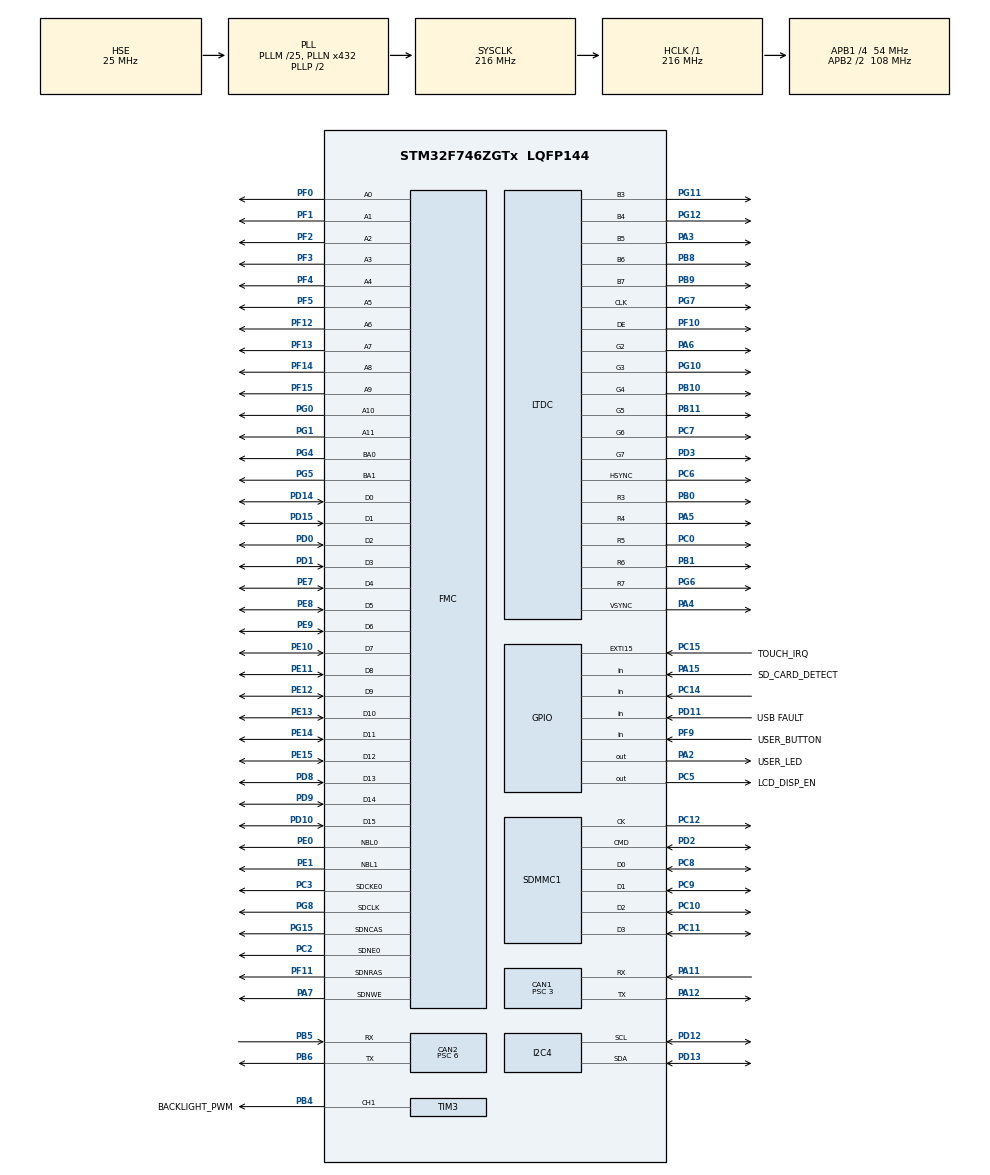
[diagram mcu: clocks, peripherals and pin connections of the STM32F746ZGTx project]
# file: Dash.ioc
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CAN1.BS1=CAN_BS1_14TQ
CAN1.BS2=CAN_BS2_3TQ
CAN1.CalculateBaudRate=1000000
CAN1.CalculateTimeBit=1000
CAN1.CalculateTimeQuantum=55.55555555555556
CAN1.Mode=CAN_MODE_NORMAL
CAN1.NART=ENABLE
CAN1.Prescaler=3
CAN1.SJW=CAN_SJW_4TQ
CAN2.BS1=CAN_BS1_15TQ
CAN2.BS2=CAN_BS2_2TQ
CAN2.CalculateBaudRate=500000
CAN2.CalculateTimeBit=2000
CAN2.CalculateTimeQuantum=111.11111111111111
CAN2.Mode=CAN_MODE_NORMAL
CAN2.NART=ENABLE
CAN2.Prescaler=6
CAN2.SJW=CAN_SJW_2TQ
CORTEX_M7.ART_ACCELERATOR_ENABLE=1
CORTEX_M7.AccessPermission_Spec=MPU_REGION_FULL_ACCESS
CORTEX_M7.BaseAddress_Spec=0xC0000000
CORTEX_M7.CPU_DCache=Enabled
CORTEX_M7.CPU_ICache=Enabled
CORTEX_M7.Enable_Spec=MPU_REGION_ENABLE
CORTEX_M7.IsShareable_Spec=MPU_ACCESS_NOT_SHAREABLE
CORTEX_M7.MPU_Control=MPU_PRIVILEGED_DEFAULT
CORTEX_M7.Size_Spec=MPU_REGION_SIZE_8MB
CORTEX_M7.SubRegionDisable_Spec=0x00
CORTEX_M7.TypeExtField_Spec=MPU_TEX_LEVEL1
CORTEX_M7.default_mode_Activation=1
DMA2D.ColorMode=DMA2D_OUTPUT_RGB565
FATFS.BSP.number=1
FATFS._MAX_SS=4096
FATFS._USE_LFN=2
FATFS0.BSP.STBoard=false
FATFS0.BSP.api=Unknown
FATFS0.BSP.instance=PA15
FATFS0.BSP.ip=GPIO
FATFS0.BSP.mode=Input
FATFS0.BSP.name=Detect_SDIO
FATFS0.BSP.solution=PA15
FMC.CASLatency1=FMC_SDRAM_CAS_LATENCY_3
FMC.ColumnBitsNumber1=FMC_SDRAM_COLUMN_BITS_NUM_9
FMC.ExitSelfRefreshDelay1=8
FMC.LoadToActiveDelay1=2
FMC.RCDDelay1=2
FMC.RPDelay1=2
FMC.RPDelay2=2
FMC.ReadBurst1=FMC_SDRAM_RBURST_ENABLE
FMC.ReadBurst2=FMC_SDRAM_RBURST_ENABLE
FMC.ReadPipeDelay1=FMC_SDRAM_RPIPE_DELAY_2
FMC.ReadPipeDelay2=FMC_SDRAM_RPIPE_DELAY_2
FMC.RowCycleDelay1=7
FMC.RowCycleDelay2=7
FMC.SDClockPeriod1=FMC_SDRAM_CLOCK_PERIOD_2
FMC.SDClockPeriod2=FMC_SDRAM_CLOCK_PERIOD_2
FMC.SelfRefreshTime1=5
FMC.WriteRecoveryTime1=3
FREERTOS.Tasks01=defaultTask,24,2048,StartDefaultTask,Default,NULL,Dynamic,NULL,NULL;canRXTask,24,2048,StartTask02,Default,NULL,Dynamic,NULL,NULL
FREERTOS.configENABLE_FPU=1
FREERTOS.configTOTAL_HEAP_SIZE=32768
I2C4.Timing=0x20404768
LTDC.ActiveW=800
LTDC.Alpha_L0=255
LTDC.BlendingFactor1_L0=LTDC_BLENDING_FACTOR1_PAxCA
LTDC.FBStartAdress_L0=0xC0000000
LTDC.HBP=8
LTDC.HFP=8
LTDC.HSync=4
LTDC.ImageHeight_L0=480
LTDC.ImageWidth_L0=800
LTDC.Layers=0
LTDC.PixelFormat_L0=LTDC_PIXEL_FORMAT_RGB565
LTDC.VBP=8
LTDC.VFP=8
LTDC.WindowX1_L0=800
LTDC.WindowY1_L0=480
Mcu.Family=STM32F7
Mcu.Name=STM32F746ZGTx
Mcu.Package=LQFP144
NVIC.CAN1_RX0_IRQn=true\:5\:0\:false\:false\:true\:true\:true\:true\:true
NVIC.CAN1_RX1_IRQn=true\:5\:0\:false\:false\:true\:true\:true\:true\:true
NVIC.CAN1_SCE_IRQn=true\:5\:0\:false\:false\:true\:true\:true\:true\:true
NVIC.CAN1_TX_IRQn=true\:5\:0\:false\:false\:true\:true\:true\:true\:true
NVIC.CAN2_RX0_IRQn=true\:5\:0\:false\:false\:true\:true\:true\:true\:true
NVIC.CAN2_RX1_IRQn=true\:5\:0\:false\:false\:true\:true\:true\:true\:true
NVIC.CAN2_SCE_IRQn=true\:5\:0\:false\:false\:true\:true\:true\:true\:true
NVIC.CAN2_TX_IRQn=true\:5\:0\:false\:false\:true\:true\:true\:true\:true
NVIC.DMA2D_IRQn=true\:5\:0\:false\:false\:true\:true\:true\:true\:true
NVIC.LTDC_ER_IRQn=true\:5\:0\:false\:false\:true\:true\:true\:true\:true
NVIC.LTDC_IRQn=true\:5\:0\:false\:false\:true\:true\:true\:true\:true
NVIC.PriorityGroup=NVIC_PRIORITYGROUP_4
NVIC.TIM1_UP_TIM10_IRQn=true\:15\:0\:false\:false\:true\:false\:false\:true\:true
NVIC.TimeBase=TIM1_UP_TIM10_IRQn
NVIC.TimeBaseIP=TIM1
PA11.Mode=CAN_Activate
PA11.Signal=CAN1_RX
PA12.Mode=CAN_Activate
PA12.Signal=CAN1_TX
PA13.Mode=Trace_Asynchronous_SW
PA13.Signal=SYS_JTMS-SWDIO
PA14.Mode=Trace_Asynchronous_SW
PA14.Signal=SYS_JTCK-SWCLK
PA15.GPIO_Label=SD_CARD_DETECT
PA15.Signal=GPIO_Input
PA2.GPIO_Label=USER_LED
PA2.Signal=GPIO_Output
PA3.Mode=RGB565
PA3.Signal=LTDC_B5
PA4.Mode=RGB565
PA4.Signal=LTDC_VSYNC
PA5.Mode=RGB565
PA5.Signal=LTDC_R4
PA6.Mode=RGB565
PA6.Signal=LTDC_G2
PA7.Signal=FMC_SDNWE
PB0.Mode=RGB565
PB0.Signal=LTDC_R3
PB1.Mode=RGB565
PB1.Signal=LTDC_R6
PB10.Mode=RGB565
PB10.Signal=LTDC_G4
PB11.Mode=RGB565
PB11.Signal=LTDC_G5
PB3.Mode=Trace_Asynchronous_SW
PB3.Signal=SYS_JTDO-SWO
PB4.GPIO_Label=BACKLIGHT_PWM
PB4.Signal=S_TIM3_CH1
PB5.Mode=CAN_Activate
PB5.Signal=CAN2_RX
PB6.Mode=CAN_Activate
PB6.Signal=CAN2_TX
PB8.Mode=RGB565
PB8.Signal=LTDC_B6
PB9.Mode=RGB565
PB9.Signal=LTDC_B7
PC0.Mode=RGB565
PC0.Signal=LTDC_R5
PC10.GPIO_PuPd=GPIO_NOPULL
PC10.GPIO_Speed_High_Default=GPIO_SPEED_FREQ_LOW
PC10.Mode=SD_4_bits_Wide_bus
PC10.Signal=SDMMC1_D2
PC11.GPIO_PuPd=GPIO_NOPULL
PC11.GPIO_Speed_High_Default=GPIO_SPEED_FREQ_LOW
PC11.Mode=SD_4_bits_Wide_bus
PC11.Signal=SDMMC1_D3
PC12.GPIO_Speed_High_Default=GPIO_SPEED_FREQ_LOW
PC12.Mode=SD_4_bits_Wide_bus
PC12.Signal=SDMMC1_CK
PC14/OSC32_IN.Signal=GPIO_Input
PC15/OSC32_OUT.GPIO_Label=TOUCH_IRQ
PC15/OSC32_OUT.Signal=GPXTI15
PC2.Mode=SdramChipSelect1_1
PC2.Signal=FMC_SDNE0
PC3.Mode=SdramChipSelect1_1
PC3.Signal=FMC_SDCKE0
PC5.GPIO_Label=LCD_DISP_EN
PC5.Signal=GPIO_Output
PC6.Mode=RGB565
PC6.Signal=LTDC_HSYNC
PC7.Mode=RGB565
PC7.Signal=LTDC_G6
PC8.GPIO_PuPd=GPIO_NOPULL
PC8.GPIO_Speed_High_Default=GPIO_SPEED_FREQ_LOW
PC8.Mode=SD_4_bits_Wide_bus
PC8.Signal=SDMMC1_D0
PC9.GPIO_PuPd=GPIO_NOPULL
PC9.GPIO_Speed_High_Default=GPIO_SPEED_FREQ_LOW
PC9.Mode=SD_4_bits_Wide_bus
PC9.Signal=SDMMC1_D1
PD0.Signal=FMC_D2_DA2
PD1.Signal=FMC_D3_DA3
PD10.Signal=FMC_D15_DA15
PD11.GPIO_Label=USB FAULT
PD11.Signal=GPIO_Input
PD12.Mode=I2C
PD12.Signal=I2C4_SCL
PD13.Mode=I2C
PD13.Signal=I2C4_SDA
PD14.Signal=FMC_D0_DA0
PD15.Signal=FMC_D1_DA1
PD2.GPIO_PuPd=GPIO_NOPULL
PD2.GPIO_Speed_High_Default=GPIO_SPEED_FREQ_LOW
PD2.Mode=SD_4_bits_Wide_bus
PD2.Signal=SDMMC1_CMD
PD3.Mode=RGB565
PD3.Signal=LTDC_G7
PD8.Signal=FMC_D13_DA13
PD9.Signal=FMC_D14_DA14
PE0.Signal=FMC_NBL0
PE1.Signal=FMC_NBL1
PE10.Signal=FMC_D7_DA7
PE11.Signal=FMC_D8_DA8
PE12.Signal=FMC_D9_DA9
PE13.Signal=FMC_D10_DA10
PE14.Signal=FMC_D11_DA11
PE15.Signal=FMC_D12_DA12
PE2.Signal=SPI4_SCK
PE4.Signal=SPI4_NSS
PE5.Signal=SPI4_MISO
PE6.Signal=SPI4_MOSI
PE7.Signal=FMC_D4_DA4
PE8.Signal=FMC_D5_DA5
PE9.Signal=FMC_D6_DA6
PF0.Signal=FMC_A0
PF1.Signal=FMC_A1
PF10.Mode=RGB565
PF10.Signal=LTDC_DE
PF11.Signal=FMC_SDNRAS
PF12.Signal=FMC_A6
PF13.Signal=FMC_A7
PF14.Signal=FMC_A8
PF15.Signal=FMC_A9
PF2.Signal=FMC_A2
PF3.Signal=FMC_A3
PF4.Signal=FMC_A4
PF5.Signal=FMC_A5
PF9.GPIO_Label=USER_BUTTON
PF9.Signal=GPIO_Input
PG0.Signal=FMC_A10
PG1.Signal=FMC_A11
PG10.Mode=RGB565
PG10.Signal=LTDC_G3
PG11.Mode=RGB565
PG11.Signal=LTDC_B3
PG12.Mode=RGB565
PG12.Signal=LTDC_B4
PG15.Signal=FMC_SDNCAS
PG4.Signal=FMC_A14_BA0
PG5.Signal=FMC_A15_BA1
PG6.Mode=RGB565
PG6.Signal=LTDC_R7
PG7.Mode=RGB565
PG7.Signal=LTDC_CLK
PG8.Signal=FMC_SDCLK
PH0/OSC_IN.Mode=HSE-External-Oscillator
PH0/OSC_IN.Signal=RCC_OSC_IN
PH1/OSC_OUT.Mode=HSE-External-Oscillator
PH1/OSC_OUT.Signal=RCC_OSC_OUT
ProjectManager.HeapSize=0x400
ProjectManager.StackSize=0x1000
ProjectManager.TargetToolchain=CMake
RCC.AHBFreq_Value=216000000
RCC.APB1CLKDivider=RCC_HCLK_DIV4
RCC.APB1Freq_Value=54000000
RCC.APB1TimFreq_Value=108000000
RCC.APB2CLKDivider=RCC_HCLK_DIV2
RCC.APB2Freq_Value=108000000
RCC.APB2TimFreq_Value=216000000
RCC.CortexFreq_Value=216000000
RCC.HCLKFreq_Value=216000000
RCC.HSE_VALUE=25000000
RCC.HSI_VALUE=16000000
RCC.LSE_VALUE=32768
RCC.PLLM=25
RCC.PLLN=432
RCC.PLLQ=9
RCC.PLLSAIN=100
RCC.PLLSourceVirtual=RCC_PLLSOURCE_HSE
RCC.SDMMCClockSelection=RCC_SDMMC1CLKSOURCE_CLK48
RCC.SYSCLKFreq_VALUE=216000000
RCC.SYSCLKSource=RCC_SYSCLKSOURCE_PLLCLK
RCC.USBFreq_Value=48000000
RCC.VCOOutputFreq_Value=432000000
SDMMC1.ClockDiv=8
SH.FMC_A0.0=FMC_A0,12b-sda1
SH.FMC_A1.0=FMC_A1,12b-sda1
SH.FMC_A10.0=FMC_A10,12b-sda1
SH.FMC_A11.0=FMC_A11,12b-sda1
SH.FMC_A14_BA0.0=FMC_BA0,FourSdramBanks1
SH.FMC_A15_BA1.0=FMC_BA1,FourSdramBanks1
SH.FMC_A2.0=FMC_A2,12b-sda1
SH.FMC_A3.0=FMC_A3,12b-sda1
SH.FMC_A4.0=FMC_A4,12b-sda1
SH.FMC_A5.0=FMC_A5,12b-sda1
SH.FMC_A6.0=FMC_A6,12b-sda1
SH.FMC_A7.0=FMC_A7,12b-sda1
SH.FMC_A8.0=FMC_A8,12b-sda1
SH.FMC_A9.0=FMC_A9,12b-sda1
SH.FMC_D0_DA0.0=FMC_D0,sd-16b-d1
SH.FMC_D10_DA10.0=FMC_D10,sd-16b-d1
SH.FMC_D11_DA11.0=FMC_D11,sd-16b-d1
SH.FMC_D12_DA12.0=FMC_D12,sd-16b-d1
SH.FMC_D13_DA13.0=FMC_D13,sd-16b-d1
SH.FMC_D14_DA14.0=FMC_D14,sd-16b-d1
SH.FMC_D15_DA15.0=FMC_D15,sd-16b-d1
SH.FMC_D1_DA1.0=FMC_D1,sd-16b-d1
SH.FMC_D2_DA2.0=FMC_D2,sd-16b-d1
SH.FMC_D3_DA3.0=FMC_D3,sd-16b-d1
SH.FMC_D4_DA4.0=FMC_D4,sd-16b-d1
SH.FMC_D5_DA5.0=FMC_D5,sd-16b-d1
SH.FMC_D6_DA6.0=FMC_D6,sd-16b-d1
SH.FMC_D7_DA7.0=FMC_D7,sd-16b-d1
SH.FMC_D8_DA8.0=FMC_D8,sd-16b-d1
SH.FMC_D9_DA9.0=FMC_D9,sd-16b-d1
SH.FMC_NBL0.0=FMC_NBL0,Sd2ByteEnable1
SH.FMC_NBL1.0=FMC_NBL1,Sd2ByteEnable1
SH.FMC_SDCLK.0=FMC_SDCLK,12b-sda1
SH.FMC_SDNCAS.0=FMC_SDNCAS,12b-sda1
SH.FMC_SDNRAS.0=FMC_SDNRAS,12b-sda1
SH.FMC_SDNWE.0=FMC_SDNWE,12b-sda1
SH.S_TIM3_CH1.0=TIM3_CH1,PWM Generation1 CH1
TIM3.Channel-PWM\ Generation1\ CH1=TIM_CHANNEL_1
TIM3.Period=10799
VP_CRC_VS_CRC.Mode=CRC_Activate
VP_DMA2D_VS_DMA2D.Mode=DMA2D_Activate
VP_FATFS_VS_SDIO.Mode=SDIO
VP_FREERTOS_VS_CMSIS_V2.Mode=CMSIS_V2
VP_SYS_VS_tim1.Mode=TIM1
board=custom

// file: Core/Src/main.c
/* USER CODE BEGIN Header */
/**
  ******************************************************************************
  * @file           : main.c
  * @brief          : Main program body
  ******************************************************************************
  * @attention
  *
  * Copyright (c) 2026 STMicroelectronics.
  * All rights reserved.
  *
  * This software is licensed under terms that can be found in the LICENSE file
  * in the root directory of this software component.
  * If no LICENSE file comes with this software, it is provided AS-IS.
  *
  ******************************************************************************
  */
/* USER CODE END Header */
#include "main.h"
#include "cmsis_os.h"
#include "can.h"
#include "crc.h"
#include "dma2d.h"
#include "fatfs.h"
#include "i2c.h"
#include "ltdc.h"
#include "sdmmc.h"
#include "tim.h"
#include "gpio.h"
#include "fmc.h"

/* USER CODE BEGIN Includes */
#include "usbd.h"
#include "usb_mode.h"
/* USER CODE END Includes */

/* USER CODE BEGIN PD */
#define SDRAM_ADDRESS_START 0xC0000000	// STM32 Memory Map
#define SDRAM_SIZE 0x1000000			// Total SDRAM # of bytes
/* USER CODE END PD */

/* USER CODE BEGIN PM */
#define TUSB_DEBUG_PRINTF(...)  my_uart_printf(__VA_ARGS__)
/* USER CODE END PM */

/* USER CODE BEGIN PV */
bool msc_mode = false;

/* USER CODE END PV */

void SystemClock_Config(void);
static void MPU_Config(void);
void MX_FREERTOS_Init(void);

int main(void)
{

  /* MPU Configuration--------------------------------------------------------*/
  MPU_Config();

  /* Enable the CPU Cache */

  /* Enable I-Cache---------------------------------------------------------*/
  SCB_EnableICache();

  /* Enable D-Cache---------------------------------------------------------*/
  SCB_EnableDCache();

  /* MCU Configuration--------------------------------------------------------*/

  /* Reset of all peripherals, Initializes the Flash interface and the Systick. */
  HAL_Init();

  /* Configure the system clock */
  SystemClock_Config();

  /* USER CODE BEGIN SysInit */

  __HAL_RCC_GPIOB_CLK_ENABLE();
  HAL_GPIO_WritePin(BACKLIGHT_PWM_GPIO_Port, BACKLIGHT_PWM_Pin, GPIO_PIN_RESET);
  GPIO_InitTypeDef backlight_early_init = {0};
  backlight_early_init.Pin = BACKLIGHT_PWM_Pin;
  backlight_early_init.Mode = GPIO_MODE_OUTPUT_PP;
  backlight_early_init.Pull = GPIO_NOPULL;
  backlight_early_init.Speed = GPIO_SPEED_FREQ_LOW;
  HAL_GPIO_Init(BACKLIGHT_PWM_GPIO_Port, &backlight_early_init);

  /* USER CODE END SysInit */

  /* Initialize all configured peripherals */
  MX_GPIO_Init();
  MX_CAN1_Init();
  MX_CAN2_Init();
  MX_FMC_Init();
  MX_LTDC_Init();
  MX_TIM3_Init();
  MX_SDMMC1_SD_Init();
  MX_FATFS_Init();
  MX_DMA2D_Init();
  MX_CRC_Init();
  MX_I2C4_Init();
  /* USER CODE BEGIN 2 */

  // Read the button state at boot to determine whether to enter MSC mode or normal mode
  msc_mode = (HAL_GPIO_ReadPin(USER_BUTTON_GPIO_Port, USER_BUTTON_Pin) == GPIO_PIN_RESET);

  // Display inits
  HAL_GPIO_WritePin(LCD_DISP_EN_GPIO_Port, LCD_DISP_EN_Pin, GPIO_PIN_SET);
  GPIO_InitTypeDef GPIO_InitStruct = {0};
  GPIO_InitStruct.Pin = BACKLIGHT_PWM_Pin;
  GPIO_InitStruct.Pull = GPIO_NOPULL;
  GPIO_InitStruct.Speed = GPIO_SPEED_FREQ_LOW;
  HAL_GPIO_WritePin(BACKLIGHT_PWM_GPIO_Port, BACKLIGHT_PWM_Pin, GPIO_PIN_SET);
  HAL_Delay(5);
  // Start the Timer in the background to configure brightness
  // (Assuming your Period is set to 10799 in tim.c, 5% is ~540)
  __HAL_TIM_SET_COMPARE(&htim3, TIM_CHANNEL_1, 1800);
  HAL_TIM_PWM_Start(&htim3, TIM_CHANNEL_1);
  // Hand the pin over to the running Timer (Alternate Function 2)
  GPIO_InitStruct.Mode = GPIO_MODE_AF_PP;
  GPIO_InitStruct.Alternate = GPIO_AF2_TIM3;
  HAL_GPIO_Init(BACKLIGHT_PWM_GPIO_Port, &GPIO_InitStruct);

  uint16_t blink_time = 500;

  /* USER CODE END 2 */

  /* Init scheduler */
  osKernelInitialize();  /* Call init function for freertos objects (in cmsis_os2.c) */
  MX_FREERTOS_Init();

  /* Start scheduler */
  osKernelStart();

  /* We should never get here as control is now taken by the scheduler */

  /* Infinite loop */
  while (1)
  {

    /* USER CODE BEGIN 3 */
    tud_task();

    // Non-blocking LED toggle every 500ms
    if (HAL_GetTick() - blink_time >= 500)
    {
        blink_time = HAL_GetTick();
        HAL_GPIO_TogglePin(USER_LED_GPIO_Port, USER_LED_Pin);
    }
  }
  /* USER CODE END 3 */
}

void SystemClock_Config(void)
{
  RCC_OscInitTypeDef RCC_OscInitStruct = {0};
  RCC_ClkInitTypeDef RCC_ClkInitStruct = {0};

  /** Configure the main internal regulator output voltage
  */
  __HAL_RCC_PWR_CLK_ENABLE();
  __HAL_PWR_VOLTAGESCALING_CONFIG(PWR_REGULATOR_VOLTAGE_SCALE1);

  /** Initializes the RCC Oscillators according to the specified parameters
  * in the RCC_OscInitTypeDef structure.
  */
  RCC_OscInitStruct.OscillatorType = RCC_OSCILLATORTYPE_HSE;
  RCC_OscInitStruct.HSEState = RCC_HSE_ON;
  RCC_OscInitStruct.PLL.PLLState = RCC_PLL_ON;
  RCC_OscInitStruct.PLL.PLLSource = RCC_PLLSOURCE_HSE;
  RCC_OscInitStruct.PLL.PLLM = 25;
  RCC_OscInitStruct.PLL.PLLN = 432;
  RCC_OscInitStruct.PLL.PLLP = RCC_PLLP_DIV2;
  RCC_OscInitStruct.PLL.PLLQ = 9;
  if (HAL_RCC_OscConfig(&RCC_OscInitStruct) != HAL_OK)
  {
    Error_Handler();
  }

  /** Activate the Over-Drive mode
  */
  if (HAL_PWREx_EnableOverDrive() != HAL_OK)
  {
    Error_Handler();
  }

  /** Initializes the CPU, AHB and APB buses clocks
  */
  RCC_ClkInitStruct.ClockType = RCC_CLOCKTYPE_HCLK|RCC_CLOCKTYPE_SYSCLK
                              |RCC_CLOCKTYPE_PCLK1|RCC_CLOCKTYPE_PCLK2;
  RCC_ClkInitStruct.SYSCLKSource = RCC_SYSCLKSOURCE_PLLCLK;
  RCC_ClkInitStruct.AHBCLKDivider = RCC_SYSCLK_DIV1;
  RCC_ClkInitStruct.APB1CLKDivider = RCC_HCLK_DIV4;
  RCC_ClkInitStruct.APB2CLKDivider = RCC_HCLK_DIV2;

  if (HAL_RCC_ClockConfig(&RCC_ClkInitStruct, FLASH_LATENCY_7) != HAL_OK)
  {
    Error_Handler();
  }
}

 /* MPU Configuration */

void MPU_Config(void)
{
  MPU_Region_InitTypeDef MPU_InitStruct = {0};

  /* Disables the MPU */
  HAL_MPU_Disable();

  /** Initializes and configures the Region and the memory to be protected
  */
  MPU_InitStruct.Enable = MPU_REGION_ENABLE;
  MPU_InitStruct.Number = MPU_REGION_NUMBER0;
  MPU_InitStruct.BaseAddress = 0xC0000000;
  MPU_InitStruct.Size = MPU_REGION_SIZE_8MB;
  MPU_InitStruct.SubRegionDisable = 0x00;
  MPU_InitStruct.TypeExtField = MPU_TEX_LEVEL1;
  MPU_InitStruct.AccessPermission = MPU_REGION_FULL_ACCESS;
  MPU_InitStruct.DisableExec = MPU_INSTRUCTION_ACCESS_DISABLE;
  MPU_InitStruct.IsShareable = MPU_ACCESS_NOT_SHAREABLE;
  MPU_InitStruct.IsCacheable = MPU_ACCESS_NOT_CACHEABLE;
  MPU_InitStruct.IsBufferable = MPU_ACCESS_NOT_BUFFERABLE;

  HAL_MPU_ConfigRegion(&MPU_InitStruct);
  /* Enables the MPU */
  HAL_MPU_Enable(MPU_PRIVILEGED_DEFAULT);

}

void HAL_TIM_PeriodElapsedCallback(TIM_HandleTypeDef *htim)
{
  if (htim->Instance == TIM1)
  {
    HAL_IncTick();
  }
}

void Error_Handler(void)
{
  __disable_irq();
  while (1)
  {
  }
}

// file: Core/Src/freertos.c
/* USER CODE BEGIN Header */
/**
  ******************************************************************************
  * File Name          : freertos.c
  * Description        : Code for freertos applications
  ******************************************************************************
  * @attention
  *
  * Copyright (c) 2026 STMicroelectronics.
  * All rights reserved.
  *
  * This software is licensed under terms that can be found in the LICENSE file
  * in the root directory of this software component.
  * If no LICENSE file comes with this software, it is provided AS-IS.
  *
  ******************************************************************************
  */
/* USER CODE END Header */

#include "FreeRTOS.h"
#include "task.h"
#include "main.h"
#include "cmsis_os.h"

/* USER CODE BEGIN Includes */
#include <stdbool.h>

#include "can.h"
#include "ltdc.h"
#include "ui.h"
#include "screen_select.h"
/* USER CODE END Includes */

/* USER CODE BEGIN PD */
#ifdef __GNUC__
#define USED __attribute__((used))
#else
#define USED
#endif

volatile const int USED uxTopUsedPriority = configMAX_PRIORITIES - 1;
/* USER CODE END PD */

/* Definitions for defaultTask */
osThreadId_t defaultTaskHandle;
const osThreadAttr_t defaultTask_attributes = {
  .name = "defaultTask",
  .stack_size = 2048 * 4,
  .priority = (osPriority_t) osPriorityNormal,
};
/* Definitions for canRXTask */
osThreadId_t canRXTaskHandle;
const osThreadAttr_t canRXTask_attributes = {
  .name = "canRXTask",
  .stack_size = 2048 * 4,
  .priority = (osPriority_t) osPriorityAboveNormal,
};

/* USER CODE BEGIN FunctionPrototypes */

#define DASH_LCD_HOR_RES 800U
#define DASH_LCD_VER_RES 480U
#define DASH_LCD_FB0_ADDR ((lv_color_t *) 0xC0000000U)
#define DASH_LCD_FB1_ADDR ((lv_color_t *) (0xC0000000U + (DASH_LCD_HOR_RES * DASH_LCD_VER_RES * sizeof(lv_color_t))))

/* Given by HAL_LTDC_ReloadEventCallback() once a flush's FBStartAdress swap
   has actually landed at the vertical blanking interval -- only then is it
   safe to let LVGL start drawing into the buffer that was just displayed. */
static osSemaphoreId_t lcd_reload_sem;

void HAL_LTDC_ReloadEventCallback(LTDC_HandleTypeDef *hltdc_arg)
{
  (void) hltdc_arg;
  osSemaphoreRelease(lcd_reload_sem);
}

static void dash_lvgl_flush_cb(lv_disp_drv_t *disp_drv, const lv_area_t *area, lv_color_t *color_p)
{
  (void) area;
  (void) color_p;

  /* In direct_mode, flush_cb is invoked once per separate invalidated
     region within a single refresh cycle, but the active buffer only
     actually swaps after the last one (see draw_buf_flush() in
     lv_refr.c). Presenting the buffer to the LTDC on every intermediate
     call would flash partially-drawn frames onto the live scan-out, so
     only push/wait on the final flush of the cycle. */
  if (!lv_disp_flush_is_last(disp_drv))
  {
    lv_disp_flush_ready(disp_drv);
    return;
  }

  /* Hand the just-rendered (off-screen) buffer to the LTDC and swap at the
     next vblank instead of mid-scan, then wait for that swap to complete
     before telling LVGL the flush is done -- this is what actually stops
     the tearing/flicker, on top of no longer sharing one buffer between
     the renderer and the live scan-out. */
  HAL_LTDC_SetAddress_NoReload(&hltdc, (uint32_t) color_p, 0);
  HAL_LTDC_Reload(&hltdc, LTDC_RELOAD_VERTICAL_BLANKING);
  osSemaphoreAcquire(lcd_reload_sem, osWaitForever);

  lv_disp_flush_ready(disp_drv);
}

/* Implemented in can.c; not declared in can.h to keep can.h HAL-callback-free */
HAL_StatusTypeDef can_bus_init(CAN_HandleTypeDef *can_s_h, CAN_HandleTypeDef *can_t_h);
void can_rx_queue_init(void);
bool can_rx_process_pending(uint32_t timeout_ms);

/* USER CODE END FunctionPrototypes */

void StartDefaultTask(void *argument);
void StartTask02(void *argument);

void MX_FREERTOS_Init(void); /* (MISRA C 2004 rule 8.1) */

void MX_FREERTOS_Init(void) {

  /* USER CODE BEGIN RTOS_QUEUES */
  /* Must exist before osKernelStart() -- the CAN RX ISR (see can.c) can start
     pushing frames onto it as soon as can_bus_init() enables interrupts,
     which happens from StartDefaultTask() right after the scheduler starts. */
  can_rx_queue_init();
  /* USER CODE END RTOS_QUEUES */

  /* Create the thread(s) */
  /* creation of defaultTask */
  defaultTaskHandle = osThreadNew(StartDefaultTask, NULL, &defaultTask_attributes);

  /* creation of canRXTask */
  canRXTaskHandle = osThreadNew(StartTask02, NULL, &canRXTask_attributes);

}

void StartDefaultTask(void *argument)
{
  /* USER CODE BEGIN StartDefaultTask */

  if (can_bus_init(&hcan1, &hcan2) != HAL_OK)
  {
    /* Do not call Error_Handler() -- losing a CAN bus shouldn't halt the
       whole dashboard. Inspect can_bus_get_error() to diagnose. */
  }

  lv_init();

  lcd_reload_sem = osSemaphoreNew(1, 0, NULL);

  static lv_disp_draw_buf_t draw_buf;
  lv_disp_draw_buf_init(&draw_buf, DASH_LCD_FB0_ADDR, DASH_LCD_FB1_ADDR, DASH_LCD_HOR_RES * DASH_LCD_VER_RES);

  static lv_disp_drv_t disp_drv;
  lv_disp_drv_init(&disp_drv);
  disp_drv.hor_res = DASH_LCD_HOR_RES;
  disp_drv.ver_res = DASH_LCD_VER_RES;
  disp_drv.draw_buf = &draw_buf;
  disp_drv.flush_cb = dash_lvgl_flush_cb;
  disp_drv.direct_mode = 1;
  disp_drv.full_refresh = 0;
  lv_disp_drv_register(&disp_drv);

  ui_init();
  eez_flow_set_theme(DASH_THEME);

  /* Infinite loop */
  for(;;)
  {
    lv_tick_inc(5);
    screen_select_tick();
    ui_tick();
    lv_timer_handler();
    osDelay(5);
  }
  /* USER CODE END StartDefaultTask */
}

void StartTask02(void *argument)
{
  /* USER CODE BEGIN StartTask02 */
  /* Infinite loop */
  for(;;)
  {
    can_rx_process_pending(osWaitForever);
  }
  /* USER CODE END StartTask02 */
}
